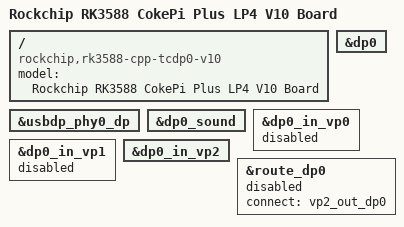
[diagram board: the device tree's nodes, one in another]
// SPDX-License-Identifier: (GPL-2.0+ OR MIT)
/*
 * Copyright (c) 2021 Rockchip Electronics Co., Ltd.
 *
 */

/dts-v1/;

#include "rk3588-cokepi-lite.dtsi"
#include "rk3588-linux.dtsi"

/ {
	model = "Rockchip RK3588 CokePi Plus LP4 V10 Board";
	compatible = "rockchip,rk3588-cpp-tcdp0-v10", "rockchip,rk3588";
};

&usbdp_phy0_dp {
	status = "okay";
};

&dp0 {
	status = "okay";
};

&dp0_sound {
	status = "okay";
};

&dp0_in_vp0 {
	status = "disabled";
};

&dp0_in_vp1 {
	status = "disabled";
};

&dp0_in_vp2 {
	status = "okay";
};

&route_dp0 {
	//status = "okay";
	status = "disabled";
	connect = <&vp2_out_dp0>;
};
